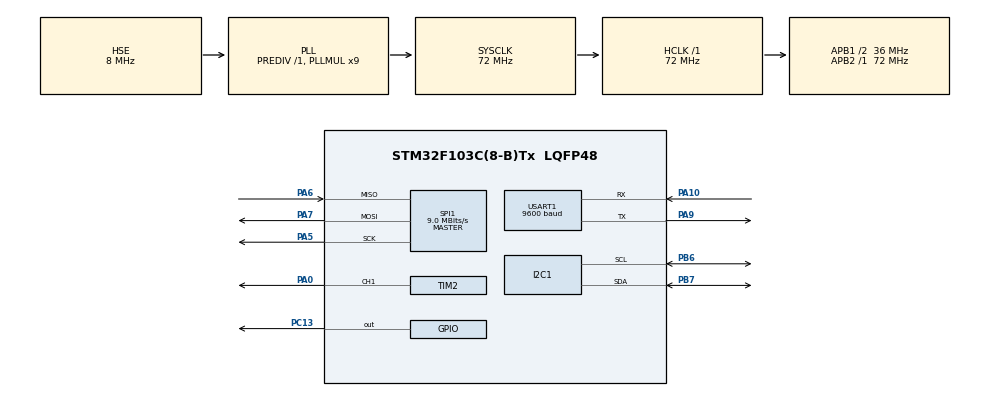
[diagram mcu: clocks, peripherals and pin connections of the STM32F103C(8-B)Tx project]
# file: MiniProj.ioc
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Dma.I2C1_RX.2.Direction=DMA_PERIPH_TO_MEMORY
Dma.I2C1_RX.2.Instance=DMA1_Channel7
Dma.I2C1_RX.2.MemDataAlignment=DMA_MDATAALIGN_BYTE
Dma.I2C1_RX.2.MemInc=DMA_MINC_ENABLE
Dma.I2C1_RX.2.Mode=DMA_NORMAL
Dma.I2C1_RX.2.PeriphDataAlignment=DMA_PDATAALIGN_BYTE
Dma.I2C1_RX.2.PeriphInc=DMA_PINC_DISABLE
Dma.I2C1_RX.2.Priority=DMA_PRIORITY_MEDIUM
Dma.I2C1_TX.3.Direction=DMA_MEMORY_TO_PERIPH
Dma.I2C1_TX.3.Instance=DMA1_Channel6
Dma.I2C1_TX.3.MemDataAlignment=DMA_MDATAALIGN_BYTE
Dma.I2C1_TX.3.MemInc=DMA_MINC_ENABLE
Dma.I2C1_TX.3.Mode=DMA_NORMAL
Dma.I2C1_TX.3.PeriphDataAlignment=DMA_PDATAALIGN_BYTE
Dma.I2C1_TX.3.PeriphInc=DMA_PINC_DISABLE
Dma.I2C1_TX.3.Priority=DMA_PRIORITY_MEDIUM
Dma.Request0=USART1_RX
Dma.Request1=USART1_TX
Dma.Request2=I2C1_RX
Dma.Request3=I2C1_TX
Dma.Request4=SPI1_RX
Dma.Request5=SPI1_TX
Dma.SPI1_RX.4.Direction=DMA_PERIPH_TO_MEMORY
Dma.SPI1_RX.4.Instance=DMA1_Channel2
Dma.SPI1_RX.4.MemDataAlignment=DMA_MDATAALIGN_BYTE
Dma.SPI1_RX.4.MemInc=DMA_MINC_ENABLE
Dma.SPI1_RX.4.Mode=DMA_NORMAL
Dma.SPI1_RX.4.PeriphDataAlignment=DMA_PDATAALIGN_BYTE
Dma.SPI1_RX.4.PeriphInc=DMA_PINC_DISABLE
Dma.SPI1_RX.4.Priority=DMA_PRIORITY_MEDIUM
Dma.SPI1_TX.5.Direction=DMA_MEMORY_TO_PERIPH
Dma.SPI1_TX.5.Instance=DMA1_Channel3
Dma.SPI1_TX.5.MemDataAlignment=DMA_MDATAALIGN_BYTE
Dma.SPI1_TX.5.MemInc=DMA_MINC_ENABLE
Dma.SPI1_TX.5.Mode=DMA_NORMAL
Dma.SPI1_TX.5.PeriphDataAlignment=DMA_PDATAALIGN_BYTE
Dma.SPI1_TX.5.PeriphInc=DMA_PINC_DISABLE
Dma.SPI1_TX.5.Priority=DMA_PRIORITY_MEDIUM
Dma.USART1_RX.0.Direction=DMA_PERIPH_TO_MEMORY
Dma.USART1_RX.0.Instance=DMA1_Channel5
Dma.USART1_RX.0.MemDataAlignment=DMA_MDATAALIGN_BYTE
Dma.USART1_RX.0.MemInc=DMA_MINC_ENABLE
Dma.USART1_RX.0.Mode=DMA_NORMAL
Dma.USART1_RX.0.PeriphDataAlignment=DMA_PDATAALIGN_BYTE
Dma.USART1_RX.0.PeriphInc=DMA_PINC_DISABLE
Dma.USART1_RX.0.Priority=DMA_PRIORITY_HIGH
Dma.USART1_TX.1.Direction=DMA_MEMORY_TO_PERIPH
Dma.USART1_TX.1.Instance=DMA1_Channel4
Dma.USART1_TX.1.MemDataAlignment=DMA_MDATAALIGN_BYTE
Dma.USART1_TX.1.MemInc=DMA_MINC_ENABLE
Dma.USART1_TX.1.Mode=DMA_NORMAL
Dma.USART1_TX.1.PeriphDataAlignment=DMA_PDATAALIGN_BYTE
Dma.USART1_TX.1.PeriphInc=DMA_PINC_DISABLE
Dma.USART1_TX.1.Priority=DMA_PRIORITY_HIGH
I2C1.I2C_Mode=I2C_Standard
IWDG.Prescaler=IWDG_PRESCALER_256
Mcu.Family=STM32F1
Mcu.Name=STM32F103C(8-B)Tx
Mcu.Package=LQFP48
NVIC.DMA1_Channel2_IRQn=true\:0\:0\:false\:false\:true\:false\:true\:true
NVIC.DMA1_Channel3_IRQn=true\:0\:0\:false\:false\:true\:false\:true\:true
NVIC.DMA1_Channel4_IRQn=true\:0\:0\:false\:false\:true\:false\:true\:true
NVIC.DMA1_Channel5_IRQn=true\:0\:0\:false\:false\:true\:false\:true\:true
NVIC.DMA1_Channel6_IRQn=true\:0\:0\:false\:false\:true\:false\:true\:true
NVIC.DMA1_Channel7_IRQn=true\:0\:0\:false\:false\:true\:false\:true\:true
NVIC.I2C1_ER_IRQn=true\:0\:0\:false\:false\:true\:true\:true\:true
NVIC.I2C1_EV_IRQn=true\:0\:0\:false\:false\:true\:true\:true\:true
NVIC.PriorityGroup=NVIC_PRIORITYGROUP_4
NVIC.SPI1_IRQn=true\:0\:0\:false\:false\:true\:true\:true\:true
NVIC.TIM1_UP_IRQn=true\:0\:0\:false\:false\:true\:true\:true\:true
NVIC.USART1_IRQn=true\:0\:0\:false\:false\:true\:true\:true\:true
PA0-WKUP.Signal=S_TIM2_CH1_ETR
PA10.Mode=Asynchronous
PA10.Signal=USART1_RX
PA13.Mode=Serial_Wire
PA13.Signal=SYS_JTMS-SWDIO
PA14.Mode=Serial_Wire
PA14.Signal=SYS_JTCK-SWCLK
PA5.Mode=Full_Duplex_Master
PA5.Signal=SPI1_SCK
PA6.Mode=Full_Duplex_Master
PA6.Signal=SPI1_MISO
PA7.Mode=Full_Duplex_Master
PA7.Signal=SPI1_MOSI
PA9.Mode=Asynchronous
PA9.Signal=USART1_TX
PB6.Mode=I2C
PB6.Signal=I2C1_SCL
PB7.Mode=I2C
PB7.Signal=I2C1_SDA
PC13-TAMPER-RTC.Signal=GPIO_Output
PC14-OSC32_IN.Mode=LSE-External-Oscillator
PC14-OSC32_IN.Signal=RCC_OSC32_IN
PC15-OSC32_OUT.Mode=LSE-External-Oscillator
PC15-OSC32_OUT.Signal=RCC_OSC32_OUT
PD0-OSC_IN.Mode=HSE-External-Oscillator
PD0-OSC_IN.Signal=RCC_OSC_IN
PD1-OSC_OUT.Mode=HSE-External-Oscillator
PD1-OSC_OUT.Signal=RCC_OSC_OUT
ProjectManager.HeapSize=0x200
ProjectManager.StackSize=0x400
ProjectManager.TargetToolchain=CMake
RCC.AHBFreq_Value=72000000
RCC.APB1CLKDivider=RCC_HCLK_DIV2
RCC.APB1Freq_Value=36000000
RCC.APB1TimFreq_Value=72000000
RCC.APB2Freq_Value=72000000
RCC.APB2TimFreq_Value=72000000
RCC.HCLKFreq_Value=72000000
RCC.PLLMUL=RCC_PLL_MUL9
RCC.PLLSourceVirtual=RCC_PLLSOURCE_HSE
RCC.RCC_MCOSource=RCC_MCO1SOURCE_PLLCLK
RCC.SYSCLKFreq_VALUE=72000000
RCC.SYSCLKSource=RCC_SYSCLKSOURCE_PLLCLK
RCC.USBFreq_Value=72000000
SH.S_TIM2_CH1_ETR.0=TIM2_CH1,PWM Generation1 CH1
SPI1.BaudRatePrescaler=SPI_BAUDRATEPRESCALER_8
SPI1.CalculateBaudRate=9.0 MBits/s
SPI1.Direction=SPI_DIRECTION_2LINES
SPI1.Mode=SPI_MODE_MASTER
SPI1.VirtualType=VM_MASTER
TIM1.Period=999
TIM1.Prescaler=71
TIM2.AutoReloadPreload=TIM_AUTORELOAD_PRELOAD_ENABLE
TIM2.Channel-PWM\ Generation1\ CH1=TIM_CHANNEL_1
TIM2.OC1Preload_PWM=ENABLE
TIM2.Period=999
TIM2.Prescaler=71
USART1.BaudRate=9600
USART1.VirtualMode=VM_ASYNC
VP_CRC_VS_CRC.Mode=CRC_Activate
VP_IWDG_VS_IWDG.Mode=IWDG_Activate
VP_TIM1_VS_ClockSourceINT.Mode=Internal
VP_TIM2_VS_ClockSourceINT.Mode=Internal
board=custom

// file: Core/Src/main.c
/* USER CODE BEGIN Header */
/**
  ******************************************************************************
  * @file           : main.c
  * @brief          : Main program body
  ******************************************************************************
  * @attention
  *
  * Copyright (c) 2026 STMicroelectronics.
  * All rights reserved.
  *
  * This software is licensed under terms that can be found in the LICENSE file
  * in the root directory of this software component.
  * If no LICENSE file comes with this software, it is provided AS-IS.
  *
  ******************************************************************************
  */
/* USER CODE END Header */
#include "main.h"
#include "crc.h"
#include "dma.h"
#include "i2c.h"
#include "iwdg.h"
#include "spi.h"
#include "tim.h"
#include "usart.h"
#include "gpio.h"

/* USER CODE BEGIN Includes */
#include "usrDefine.h"
/* USER CODE END Includes */

void SystemClock_Config(void);

int main(void)
{

  /* MCU Configuration--------------------------------------------------------*/

  /* Reset of all peripherals, Initializes the Flash interface and the Systick. */
  HAL_Init();

  /* Configure the system clock */
  SystemClock_Config();

  /* Initialize all configured peripherals */
  MX_GPIO_Init();
  MX_DMA_Init();
  MX_TIM1_Init();
  MX_USART1_UART_Init();
  MX_TIM2_Init();
  MX_CRC_Init();
  MX_I2C1_Init();
  MX_SPI1_Init();
  MX_IWDG_Init();
  /* USER CODE BEGIN 2 */
  bsp_peripheral_init();
  appLayer_init();
  /* USER CODE END 2 */

  /* Infinite loop */
  /* USER CODE BEGIN WHILE */
  while (1)
  {
    if(bsp_delayNonBlocking_ms(10000)){
      /* IWDG 26s */
      HAL_IWDG_Refresh(&hiwdg);
    }

    taskScheduler_running();

    /* USER CODE END WHILE */

  }
}

void SystemClock_Config(void)
{
  RCC_OscInitTypeDef RCC_OscInitStruct = {0};
  RCC_ClkInitTypeDef RCC_ClkInitStruct = {0};

  /** Initializes the RCC Oscillators according to the specified parameters
  * in the RCC_OscInitTypeDef structure.
  */
  RCC_OscInitStruct.OscillatorType = RCC_OSCILLATORTYPE_LSI|RCC_OSCILLATORTYPE_HSE;
  RCC_OscInitStruct.HSEState = RCC_HSE_ON;
  RCC_OscInitStruct.HSEPredivValue = RCC_HSE_PREDIV_DIV1;
  RCC_OscInitStruct.HSIState = RCC_HSI_ON;
  RCC_OscInitStruct.LSIState = RCC_LSI_ON;
  RCC_OscInitStruct.PLL.PLLState = RCC_PLL_ON;
  RCC_OscInitStruct.PLL.PLLSource = RCC_PLLSOURCE_HSE;
  RCC_OscInitStruct.PLL.PLLMUL = RCC_PLL_MUL9;
  if (HAL_RCC_OscConfig(&RCC_OscInitStruct) != HAL_OK)
  {
    Error_Handler();
  }

  /** Initializes the CPU, AHB and APB buses clocks
  */
  RCC_ClkInitStruct.ClockType = RCC_CLOCKTYPE_HCLK|RCC_CLOCKTYPE_SYSCLK
                              |RCC_CLOCKTYPE_PCLK1|RCC_CLOCKTYPE_PCLK2;
  RCC_ClkInitStruct.SYSCLKSource = RCC_SYSCLKSOURCE_PLLCLK;
  RCC_ClkInitStruct.AHBCLKDivider = RCC_SYSCLK_DIV1;
  RCC_ClkInitStruct.APB1CLKDivider = RCC_HCLK_DIV2;
  RCC_ClkInitStruct.APB2CLKDivider = RCC_HCLK_DIV1;

  if (HAL_RCC_ClockConfig(&RCC_ClkInitStruct, FLASH_LATENCY_2) != HAL_OK)
  {
    Error_Handler();
  }
}

void Error_Handler(void)
{
  __disable_irq();
  while (1)
  {
  }
}
